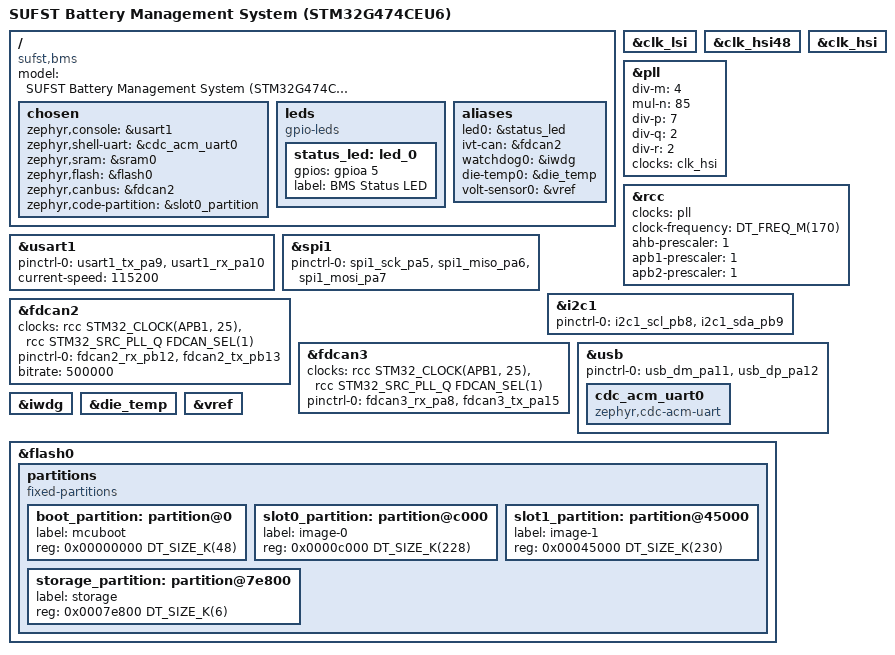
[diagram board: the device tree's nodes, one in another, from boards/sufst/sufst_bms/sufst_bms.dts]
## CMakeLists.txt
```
cmake_minimum_required(VERSION 3.20.0)

# Automatically discover custom boards defined in this repository's boards/ folder
list(APPEND BOARD_ROOT ${CMAKE_CURRENT_SOURCE_DIR})

find_package(Zephyr REQUIRED HINTS $ENV{ZEPHYR_BASE})
project(sufst_bms LANGUAGES C)

target_include_directories(app PRIVATE include)

target_sources(app PRIVATE
    src/main.c
    src/bms_sm.c
    src/bms_safety.c
    src/drv3946.c
    src/bms_hv_sense.c
    src/bms_shell.c
    src/bms_usb.c
    src/ivt_s.c
)
```

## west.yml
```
manifest:
  remotes:
    - name: zephyrproject-rtos
      url-base: https://github.com/zephyrproject-rtos

  defaults:
    remote: zephyrproject-rtos

  projects:
    - name: zephyr
      revision: v4.4.0
      import:
        name-allowlist:
          - cmsis
          - cmsis_6
          - hal_stm32
          - percepio
          - picolibc
          - mcuboot
          - segger
          - mbedtls

  self:
    path: app
```

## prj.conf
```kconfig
# Base Zephyr OS Configuration for SUFST BMS
CONFIG_MAIN_STACK_SIZE=2048
CONFIG_SYSTEM_WORKQUEUE_STACK_SIZE=2048

# Hardware Peripherals
CONFIG_GPIO=y
CONFIG_SPI=y
CONFIG_ADC=y
CONFIG_CAN=y
CONFIG_SERIAL=y
CONFIG_CONSOLE=y
CONFIG_UART_CONSOLE=y

# USB CDC-ACM virtual COM port carrying the Zephyr shell ("bms" commands)
CONFIG_USB_DEVICE_STACK_NEXT=y
CONFIG_CDC_ACM_SERIAL_INITIALIZE_AT_BOOT=y
CONFIG_CDC_ACM_SERIAL_MANUFACTURER_STRING="SUFST"
CONFIG_CDC_ACM_SERIAL_PRODUCT_STRING="SUFST BMS"
CONFIG_CDC_ACM_SERIAL_SELF_POWERED=y
CONFIG_UART_LINE_CTRL=y
CONFIG_SHELL=y
CONFIG_SHELL_BACKEND_SERIAL_CHECK_DTR=y

# Logging
CONFIG_LOG=y
CONFIG_LOG_DEFAULT_LEVEL=3
```

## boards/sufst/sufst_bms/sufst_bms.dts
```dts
/*
 * SUFST BMS Custom Board DeviceTree (STM32G474CEU6 - UFQFPN48)
 * SPDX-License-Identifier: Apache-2.0
 */

/dts-v1/;
#include <st/g4/stm32g474Xe.dtsi>
#include <st/g4/stm32g474c(b-c-e)ux-pinctrl.dtsi>

/ {
	model = "SUFST Battery Management System (STM32G474CEU6)";
	compatible = "sufst,bms", "st,stm32g474";

	chosen {
		zephyr,console = &usart1;
		zephyr,shell-uart = &cdc_acm_uart0;
		zephyr,sram = &sram0;
		zephyr,flash = &flash0;
		zephyr,canbus = &fdcan2;
		zephyr,code-partition = &slot0_partition;
	};

	leds: leds {
		compatible = "gpio-leds";

		status_led: led_0 {
			/* Update pin to match BMS schematic status LED */
			gpios = <&gpioa 5 GPIO_ACTIVE_HIGH>;
			label = "BMS Status LED";
		};
	};

	aliases {
		led0 = &status_led;
		ivt-can = &fdcan2;
		watchdog0 = &iwdg;
		die-temp0 = &die_temp;
		volt-sensor0 = &vref;
	};
};

&clk_lsi {
	status = "okay";
};

&clk_hsi48 {
	status = "okay";
};

/*
 * Default clock setup uses internal 16 MHz HSI -> PLL -> 170 MHz SYSCLK
 * so the board boots without depending on an external crystal.
 * When using an external HSE crystal on the PCB, enable &clk_hse and
 * switch &pll clocks to <&clk_hse>.
 */
&clk_hsi {
	status = "okay";
};

&pll {
	div-m = <4>;
	mul-n = <85>;
	div-p = <7>;
	div-q = <2>;
	div-r = <2>;
	clocks = <&clk_hsi>;
	status = "okay";
};

&rcc {
	clocks = <&pll>;
	clock-frequency = <DT_FREQ_M(170)>;
	ahb-prescaler = <1>;
	apb1-prescaler = <1>;
	apb2-prescaler = <1>;
};

&usart1 {
	pinctrl-0 = <&usart1_tx_pa9 &usart1_rx_pa10>;
	pinctrl-names = "default";
	current-speed = <115200>;
	status = "okay";
};

&spi1 {
	pinctrl-0 = <&spi1_sck_pa5 &spi1_miso_pa6 &spi1_mosi_pa7>;
	pinctrl-names = "default";
	status = "okay";
};

&i2c1 {
	pinctrl-0 = <&i2c1_scl_pb8 &i2c1_sda_pb9>;
	pinctrl-names = "default";
	status = "okay";
};

/*
 * PA11 / PA12 are the only USB D- / D+ pins on the 48-pin package, so CAN
 * uses FDCAN2 and FDCAN3 instead of FDCAN1. Pin choices are placeholders
 * until the PCB is final (alternatives: FDCAN2 on PB5/PB6, FDCAN3 on PB3/PB4,
 * FDCAN1 on PB8/PB9 - note PB8 is BOOT0).
 */
&fdcan2 {
	clocks = <&rcc STM32_CLOCK(APB1, 25)>,
		 <&rcc STM32_SRC_PLL_Q FDCAN_SEL(1)>;
	pinctrl-0 = <&fdcan2_rx_pb12 &fdcan2_tx_pb13>;
	pinctrl-names = "default";
	bitrate = <500000>; /* IVT-S factory default */
	status = "okay";
};

&fdcan3 {
	clocks = <&rcc STM32_CLOCK(APB1, 25)>,
		 <&rcc STM32_SRC_PLL_Q FDCAN_SEL(1)>;
	pinctrl-0 = <&fdcan3_rx_pa8 &fdcan3_tx_pa15>;
	pinctrl-names = "default";
	status = "okay";
};

/*
 * USB full-speed device, clocked from HSI48 (default CLK48 source). HSI48 is
 * trimmed against USB SOF by the CRS, enabled in src/bms_usb.c.
 */
zephyr_udc0: &usb {
	pinctrl-0 = <&usb_dm_pa11 &usb_dp_pa12>;
	pinctrl-names = "default";
	status = "okay";

	cdc_acm_uart0: cdc_acm_uart0 {
		compatible = "zephyr,cdc-acm-uart";
	};
};

&iwdg {
	status = "okay";
};

&die_temp {
	status = "okay";
};

&vref {
	status = "okay";
};

&flash0 {
	partitions {
		compatible = "fixed-partitions";
		#address-cells = <1>;
		#size-cells = <1>;

		boot_partition: partition@0 {
			label = "mcuboot";
			reg = <0x00000000 DT_SIZE_K(48)>;
		};

		slot0_partition: partition@c000 {
			label = "image-0";
			reg = <0x0000c000 DT_SIZE_K(228)>;
		};

		slot1_partition: partition@45000 {
			label = "image-1";
			reg = <0x00045000 DT_SIZE_K(230)>;
		};

		storage_partition: partition@7e800 {
			label = "storage";
			reg = <0x0007e800 DT_SIZE_K(6)>;
		};
	};
};
```

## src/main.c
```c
#include <zephyr/kernel.h>
#include <zephyr/logging/log.h>

#include "bms.h"

LOG_MODULE_REGISTER(bms_main, LOG_LEVEL_INF);

static struct bms_ctx bms;
static K_MUTEX_DEFINE(bms_mutex);

struct bms_ctx *bms_ctx_get(void)
{
	return &bms;
}

void bms_ctx_lock(void)
{
	k_mutex_lock(&bms_mutex, K_FOREVER);
}

void bms_ctx_unlock(void)
{
	k_mutex_unlock(&bms_mutex);
}

/**
 * @brief Temporary stub to populate nominal cell & AMC3330 measurements
 *        until the physical ADC/GPIO pins and AFE driver are wired up.
 */
static void update_mock_measurements(struct bms_ctx *ctx)
{
	ctx->afe_init_ok      = true;
	ctx->last_afe_rx_ms   = k_uptime_get();
	ctx->min_cell_mv      = 3700U;   /* 3.70 V */
	ctx->max_cell_mv      = 3720U;   /* 3.72 V */
	ctx->min_temp_deci_c  = 240;     /* 24.0 C */
	ctx->max_temp_deci_c  = 265;     /* 26.5 C */
	ctx->sum_cells_mv     = 371000U; /* 371.0 V */

	/* Mock AMC3330 U4 (ACCU) & U3 (DC-LINK) differential outputs + DIAG pins */
	ctx->hv_sense.accu.mock_diag_ok   = true;
	ctx->hv_sense.accu.mock_diff_mv   = amc3330_hv_mv_to_diff_mv(371000U); /* ~1067 mV diff */
	ctx->hv_sense.dclink.mock_diag_ok = true;
	ctx->hv_sense.dclink.mock_diff_mv = amc3330_hv_mv_to_diff_mv(0U);      /* 0 V when AIRs open */
}

/**
 * @brief Pull the latest IVT-S readings into the BMS context.
 */
static void update_current_measurement(struct bms_ctx *ctx)
{
	ivt_s_get(&ctx->ivt);

	if (ctx->ivt.ch[IVT_S_CH_I].seen) {
		ctx->pack_current_ma   = BMS_CURRENT_SENSOR_SIGN * ctx->ivt.ch[IVT_S_CH_I].value;
		ctx->current_sensor_ok = true;
	}
}

int main(void)
{
	LOG_INF("SUFST BMS Firmware Initialized (%s)", CONFIG_BOARD_TARGET);

	bms_ctx_lock();
	bms_sm_init(&bms);
	bms_ctx_unlock();

	if (ivt_s_init() < 0) {
		LOG_ERR("IVT-S current sensor CAN init failed; BMS will stay in INIT");
	}

	while (1) {
		bms_ctx_lock();
		update_mock_measurements(&bms);
		update_current_measurement(&bms);
		bms_sm_tick(&bms);
		bms_safety_check(&bms, BMS_SM_TICK_MS);
		bms_ctx_unlock();

		k_sleep(K_MSEC(BMS_SM_TICK_MS));
	}

	return 0;
}
```

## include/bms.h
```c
#ifndef SUFST_BMS_H_
#define SUFST_BMS_H_

/**
 * @file bms.h
 * @brief SUFST BMS core data structures, safety limits, fault flags,
 *        and state machine / safety monitor API.
 */

#include <stdbool.h>
#include <stdint.h>

#include "bms_hv_sense.h"
#include "drv3946.h"
#include "ivt_s.h"

/* ==========================================================================
 * Timing & Precharge Configuration Constants
 * ========================================================================== */

/** Periodic state machine & safety monitor tick interval (ms) */
#define BMS_SM_TICK_MS                     50U

/** Mechanical relay settling delay between sequenced contactor steps (ms) */
#define BMS_RELAY_SETTLE_MS                100U

/** Maximum allowed time in PRECHARGE_WAIT before faulting (ms) */
#define BMS_PRECHARGE_TIMEOUT_MS           3000U

/** Minimum time in PRECHARGE_WAIT before checking voltage threshold (ms) */
#define BMS_PRECHARGE_MIN_TIME_MS          500U

/** Precharge complete threshold: TS voltage >= 95% of pack voltage */
#define BMS_PRECHARGE_THRESHOLD_PCT        95U

/* ==========================================================================
 * Safety Threshold Constants (Standard Li-Ion / Formula Student EV Defaults)
 * ========================================================================== */

/** Maximum allowed single cell voltage (4.200 V) */
#define BMS_CELL_MAX_MV                    4200U

/** Minimum allowed single cell voltage (2.500 V) */
#define BMS_CELL_MIN_MV                    2500U

/** Implausibly high cell reading -> sensor/sense-wire fault (5.000 V) */
#define BMS_CELL_IMPLAUSIBLE_HIGH_MV       5000U

/** Implausibly low cell reading -> sensor/sense-wire fault (0.500 V) */
#define BMS_CELL_IMPLAUSIBLE_LOW_MV        500U

/** Maximum allowed cell temperature in 0.1 deg C (60.0 C per FS EV rules) */
#define BMS_TEMP_MAX_DECI_C                600

/** Minimum allowed cell temperature in 0.1 deg C (-20.0 C) */
#define BMS_TEMP_MIN_DECI_C                (-200)

/** Implausibly high temperature reading in 0.1 deg C (120.0 C, shorted NTC) */
#define BMS_TEMP_IMPLAUSIBLE_HIGH_DECI_C   1200

/** Implausibly low temperature reading in 0.1 deg C (-40.0 C, open NTC) */
#define BMS_TEMP_IMPLAUSIBLE_LOW_DECI_C    (-400)

/**
 * Maximum allowed discharge current in mA (200.0 A, pack_current_ma > +limit).
 * Set by the inverter's maximum DC current draw.
 */
#define BMS_CURRENT_MAX_DISCHARGE_MA       200000

/**
 * Maximum allowed regen / charge current in mA (40.5 A, pack_current_ma < -limit).
 * Pack is 140s3p Molicel INR-21700-P45B: 13.5 A max charge per cell x 3 parallel.
 */
#define BMS_CURRENT_MAX_REGEN_MA           40500

/**
 * Sign applied to the IVT-S current reading so that positive = discharge.
 * Set to -1 if the sensor is mounted with its current direction reversed.
 */
#define BMS_CURRENT_SENSOR_SIGN            1

/** Charge current magnitude above which the pack counts as "charging" (1.0 A) */
#define BMS_CHARGE_DETECT_MA               1000

/** Minimum cell temperature for charging / regen in 0.1 deg C (0.0 C) */
#define BMS_TEMP_CHARGE_MIN_DECI_C         0

/* ==========================================================================
 * Regen Derating Window (advisory limit broadcast to VCU / inverter)
 *
 * The limit ramps linearly from BMS_CURRENT_MAX_REGEN_MA at the "FULL" point
 * down to 0 at the "ZERO" point. Each ZERO point sits inside its hard fault
 * threshold so a compliant inverter never trips the BMS.
 * ========================================================================== */

/** Highest cell voltage at which full regen is still allowed (4.100 V) */
#define BMS_REGEN_FULL_CELL_MV             4100

/** Highest cell voltage at which regen is cut to zero (4.180 V) */
#define BMS_REGEN_ZERO_CELL_MV             4180

/** Lowest cell temperature at which full regen is allowed (10.0 C) */
#define BMS_REGEN_FULL_COLD_DECI_C         100

/** Lowest cell temperature at which regen is cut to zero (2.0 C) */
#define BMS_REGEN_ZERO_COLD_DECI_C         20

/** Highest cell temperature at which full regen is allowed (50.0 C) */
#define BMS_REGEN_FULL_HOT_DECI_C          500

/** Highest cell temperature at which regen is cut to zero (58.0 C) */
#define BMS_REGEN_ZERO_HOT_DECI_C          580

/** Maximum allowed mismatch between sum of cells and HV pack sensor (5.0 V) */
#define BMS_PACK_SUM_MAX_MISMATCH_MV       5000U

/* ==========================================================================
 * Fault Debounce Timings (FS EV Rule Compliant)
 * ========================================================================== */

/** Over/under-voltage debounce duration (ms) - FS max allowed: 500 ms */
#define BMS_DEBOUNCE_VOLTAGE_MS            100U

/** Over-current debounce duration (ms) - FS max allowed: 500 ms */
#define BMS_DEBOUNCE_CURRENT_MS            100U

/** Over/under-temperature debounce duration (ms) - FS max allowed: 1000 ms */
#define BMS_DEBOUNCE_TEMP_MS               500U

/** Charging below minimum charge temperature debounce duration (ms) */
#define BMS_DEBOUNCE_CHARGE_TEMP_MS        500U

/** Open-wire detection debounce duration (ms) */
#define BMS_DEBOUNCE_OPEN_WIRE_MS          100U

/** Sensor implausibility debounce duration (ms) */
#define BMS_DEBOUNCE_IMPLAUSIBLE_MS        100U

/** Maximum time without a valid AFE update before faulting (ms) */
#define BMS_AFE_COMM_TIMEOUT_MS            250U

/** Maximum time without an IVT-S current frame before faulting (ms, sensor cycle is 20 ms) */
#define BMS_CURRENT_SENSOR_TIMEOUT_MS      100U

/** IVT-S reported result / system error debounce duration (ms) */
#define BMS_DEBOUNCE_CURRENT_SENSOR_MS     100U

/* ==========================================================================
 * BMS States
 * ========================================================================== */

typedef enum {
	BMS_STATE_INIT = 0,            /**< Boot, self-test, and persistent fault check */
	BMS_STATE_STANDBY,             /**< Idle; all relays open, outputs TS_READY when SDC powered */
	BMS_STATE_PRECHARGE_CLOSE_PC,  /**< Step 1: Close Precharge first (PC=1, AIR-=0, AIR+=0) */
	BMS_STATE_PRECHARGE_WAIT,      /**< Step 2: Close AIR- & charge DC bus (PC=1, AIR-=1, AIR+=0) */
	BMS_STATE_PRECHARGE_CLOSE_POS, /**< Step 3: Close AIR+ while PC stays closed (PC=1, AIR-=1, AIR+=1) */
	BMS_STATE_PRECHARGE_OPEN_NEG,  /**< Precharge abort/fault: Open AIR- first (PC=1, AIR-=0, AIR+=0) */
	BMS_STATE_ACTIVE,              /**< Step 4: Open PC, TS active (PC=0, AIR-=1, AIR+=1) */
	BMS_STATE_CHARGING,            /**< Pack charging active (PC=0, AIR-=1, AIR+=1, balancing) */
	BMS_STATE_FAULT,               /**< Fault latched; SDC open, all relays open (PC=0, AIR-=0, AIR+=0) */
} bms_state_t;

/* ==========================================================================
 * Safety Fault Bitmask
 * ========================================================================== */

#define BMS_FAULT_NONE                (0U)
#define BMS_FAULT_CELL_OV             (1U << 0) /**< Cell over-voltage */
#define BMS_FAULT_CELL_UV             (1U << 1) /**< Cell under-voltage */
#define BMS_FAULT_OVER_TEMP           (1U << 2) /**< Cell/pack over-temperature */
#define BMS_FAULT_UNDER_TEMP          (1U << 3) /**< Cell/pack under-temperature */
#define BMS_FAULT_OVER_CURRENT        (1U << 4) /**< Pack discharge over-current */
#define BMS_FAULT_AFE_COMM            (1U << 5) /**< AFE isoSPI communication loss */
#define BMS_FAULT_OPEN_WIRE           (1U << 6) /**< Cell sense/thermistor open wire */
#define BMS_FAULT_PRECHARGE_TIMEOUT   (1U << 7) /**< Precharge failed to reach target V */
#define BMS_FAULT_IMPLAUSIBILITY      (1U << 8) /**< Sensor reading implausibility */
#define BMS_FAULT_CONTACTOR_DRV       (1U << 9) /**< DRV3946-Q1 contactor driver nFAULT / SPI error */
#define BMS_FAULT_REGEN_OVER_CURRENT  (1U << 10) /**< Pack regen / charge over-current */
#define BMS_FAULT_CHARGE_UNDER_TEMP   (1U << 11) /**< Charging / regen below minimum charge temperature */
#define BMS_FAULT_CURRENT_SENSOR      (1U << 12) /**< IVT-S current sensor timeout or reported error */

/* ==========================================================================
 * BMS Context & IO State
 * ========================================================================== */

/**
 * @brief Relay, Shutdown Circuit (SDC), and VCU handshake outputs.
 */
struct bms_outputs {
	bool precharge_closed;     /**< Precharge relay (discrete GPIO) */
	bool air_neg_closed;       /**< Low-side contactor (AIR- via DRV3946 Ch1) */
	bool air_pos_closed;       /**< High-side contactor (AIR+ via DRV3946 Ch2) */
	bool sdc_fault_pin_active; /**< GPIO output: true = open SDC relay (FAULT) */
	bool ts_ready;             /**< BMS -> VCU (CAN/GPIO): AIRs have power & SDC can close */
	bool ts_active;            /**< BMS -> VCU (CAN/GPIO): Precharge complete & both AIRs closed */
	bool balancing_enabled;    /**< Cell balancing active flag */
	bool regen_allowed;        /**< BMS -> VCU (CAN): true when max_regen_current_ma > 0 */
	uint32_t max_regen_current_ma; /**< BMS -> VCU (CAN): derated regen current limit (mA, magnitude) */
};

/**
 * @brief External commands / requests into the BMS state machine (from VCU / PC).
 */
struct bms_requests {
	bool ts_request_can;       /**< VCU -> BMS "TS REQUEST" via CAN */
	bool ts_request_gpio;      /**< VCU -> BMS "TS REQUEST" via GPIO */
	bool ts_request;           /**< Combined effective TS REQUEST signal (CAN || GPIO) */
	bool charge_enable;        /**< Request to enter CHARGING mode after precharge */
	bool pc_clear_faults;      /**< Manual fault-clear command from PC application */
};

/**
 * @brief Accumulator timers (ms) for fault condition debouncing.
 */
struct bms_safety_timers {
	uint32_t cell_ov_ms;
	uint32_t cell_uv_ms;
	uint32_t over_temp_ms;
	uint32_t under_temp_ms;
	uint32_t over_current_ms;
	uint32_t regen_over_current_ms;
	uint32_t charge_under_temp_ms;
	uint32_t current_sensor_ms;
	uint32_t open_wire_ms;
	uint32_t implausibility_ms;
};

/**
 * @brief Main BMS runtime context.
 */
struct bms_ctx {
	bms_state_t state;
	int64_t state_entry_time_ms;

	/* Hardware Drivers: DRV3946-Q1 Contactors & Dual AMC3330 HV Voltage Sense */
	DRV3946_HandleTypeDef drv_airs;
	struct bms_hv_sense   hv_sense;

	/* Fault tracking & debounce state */
	uint32_t live_faults;      /**< Currently present (debounced) fault conditions */
	uint32_t latched_faults;   /**< Persistent fault bitmask (saved across power cycles) */
	struct bms_safety_timers fault_timers;

	/* Shutdown circuit, AFE, & AMC3330 DIAG readiness monitoring */
	bool afe_init_ok;          /**< Set true once AFE passes startup self-check */
	bool hv_sense_valid;       /**< True when both AMC3330 DIAG pins (U3 & U4) are HIGH */
	bool sdc_airs_powered;     /**< Continuous sense: true when SDC is closed & AIRs have power */
	bool afe_open_wire;        /**< Reported by AFE open-wire diagnostic check */
	int64_t last_afe_rx_ms;    /**< Uptime timestamp (ms) of last valid AFE sample */

	/* IVT-S current sensor (CAN) */
	struct ivt_s_data ivt;     /**< Latest IVT-S readings (all channels) */
	bool current_sensor_ok;    /**< Set true once the first IVT-S current frame arrives */

	/* Pack & DC bus measurements (updated by sensor/AFE layer) */
	uint32_t sum_cells_mv;     /**< Sum of all individual cell voltages from AFE (mV) */
	uint32_t pack_voltage_mv;  /**< Total accumulator voltage from HV pack sensor (mV) */
	uint32_t ts_voltage_mv;    /**< Tractive System / inverter DC-link voltage (mV) */
	int32_t  pack_current_ma;  /**< Pack current from IVT-S (mA, positive = discharge) */
	uint16_t min_cell_mv;      /**< Lowest single cell voltage (mV) */
	uint16_t max_cell_mv;      /**< Highest single cell voltage (mV) */
	int16_t  min_temp_deci_c;  /**< Lowest cell temperature (0.1 deg C) */
	int16_t  max_temp_deci_c;  /**< Highest cell temperature (0.1 deg C) */

	struct bms_requests req;
	struct bms_outputs out;
};

/* ==========================================================================
 * State Machine Public API (bms_sm.c)
 * ========================================================================== */

/**
 * @brief Initialize the BMS context, load persistent faults from Flash,
 *        and set safe initial hardware outputs.
 */
void bms_sm_init(struct bms_ctx *ctx);

/**
 * @brief Execute one periodic cycle of the BMS state machine.
 *        Samples SDC / ts_request inputs, updates ts_ready, and runs state transitions.
 */
void bms_sm_tick(struct bms_ctx *ctx);

/**
 * @brief Evaluate whether the BMS is ready for Tractive System activation
 *        (no faults, AFE initialized, and AIRs have power / SDC can close).
 */
bool bms_sm_is_ts_ready(const struct bms_ctx *ctx);

/**
 * @brief Raise one or more safety fault flags. Immediately latches into
 *        non-volatile storage and initiates sequenced fault shutdown.
 */
void bms_sm_raise_fault(struct bms_ctx *ctx, uint32_t fault_mask);

/**
 * @brief Request manual clearance of latched faults (from PC application).
 *        Faults will only clear if live_faults == 0 and ts_request is off.
 */
bool bms_sm_clear_faults_from_pc(struct bms_ctx *ctx);

/**
 * @brief Convert a BMS state enum to a human-readable string.
 */
const char *bms_state_to_str(bms_state_t state);

/* ==========================================================================
 * Safety & Fault Monitor Public API (bms_safety.c)
 * ========================================================================== */

/**
 * @brief Evaluate all cell voltages, temperatures, pack current, open-wire,
 *        sensor plausibility, and AFE communication heartbeat with debouncing.
 *        Updates ctx->live_faults and raises latched faults when thresholds
 *        are exceeded for their respective debounce durations.
 *
 * @param ctx   Pointer to BMS context structure.
 * @param dt_ms Elapsed time since last check in milliseconds (e.g. BMS_SM_TICK_MS).
 */
void bms_safety_check(struct bms_ctx *ctx, uint32_t dt_ms);

/**
 * @brief Compute the derated regen current limit for the current measurements.
 *
 * Returns 0 unless the BMS is in BMS_STATE_ACTIVE with no live or latched
 * faults. Otherwise returns BMS_CURRENT_MAX_REGEN_MA scaled by the most
 * restrictive of the cell-voltage, cold-temperature and hot-temperature
 * derating ramps (see BMS_REGEN_* constants).
 *
 * @param ctx Pointer to BMS context structure.
 * @return Allowed regen current magnitude in mA.
 */
uint32_t bms_regen_limit_ma(const struct bms_ctx *ctx);

/* ==========================================================================
 * Shared Context Access (main.c)
 * ========================================================================== */

/**
 * @brief Get the single BMS context owned by the main control loop.
 *        Hold bms_ctx_lock() while reading or modifying it from another thread.
 */
struct bms_ctx *bms_ctx_get(void);

/** @brief Lock the BMS context (held by the main loop for each control tick). */
void bms_ctx_lock(void);

/** @brief Unlock the BMS context. */
void bms_ctx_unlock(void);

#endif /* SUFST_BMS_H_ */
```

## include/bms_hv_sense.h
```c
/**
 * @file bms_hv_sense.h
 * @brief AMC3330DWER Isolated High-Voltage Sensing Driver (Accumulator & DC-Link).
 *
 * Schematic Parameters (U3 = DC-Link TS, U4 = Accumulator TS):
 *   - High-side top divider:    4 x 422 kOhm in series = 1,688,000 Ohm
 *     (U3: R13+R14+R16+R18, U4: R22+R23+R25+R27)
 *   - High-side sense resistor: 2.43 kOhm = 2,430 Ohm
 *     (U3: R20, U4: R29)
 *   - AMC3330 nominal gain:     G = 2.0 V/V
 *   - Output filter:            2 x 100 Ohm + 1 nF differential RC filter
 *   - DIAG output (Pin 14):     Open-drain with 47 kOhm pull-up to +3V3
 *                               HIGH (1) = Valid reading
 *                               LOW  (0) = Invalid reading (startup / fault)
 *
 * Transfer Function:
 *   V_diff = V_OUTP - V_OUTN = 2.0 * V_HV * (R_bot / (R_top + R_bot))
 *   V_HV   = V_diff * (R_top + R_bot) / (2.0 * R_bot)
 *          = V_diff * (1,688,000 + 2,430) / (2 * 2,430)
 *          = V_diff * 1,690,430 / 4,860
 *          ~= V_diff * 347.8251
 */

#ifndef SUFST_BMS_HV_SENSE_H_
#define SUFST_BMS_HV_SENSE_H_

#include <stdbool.h>
#include <stdint.h>
#include <zephyr/drivers/adc.h>
#include <zephyr/drivers/gpio.h>

#ifdef __cplusplus
extern "C" {
#endif

/* ==========================================================================
 * Schematic Resistor & AMC3330 Constants
 * ========================================================================== */

/** Top series divider resistance: 4 * 422 kOhm = 1,688,000 Ohm */
#define AMC3330_R_TOP_OHM          (4ULL * 422000ULL)

/** Bottom sense resistance: 2.43 kOhm = 2,430 Ohm */
#define AMC3330_R_BOT_OHM          (2430ULL)

/** AMC3330 fixed differential voltage gain (2 V/V) */
#define AMC3330_GAIN_NUM           (2ULL)

/** Numerator for V_diff -> V_HV conversion: R_top + R_bot = 1,690,430 */
#define AMC3330_SCALE_NUM          (AMC3330_R_TOP_OHM + AMC3330_R_BOT_OHM)

/** Denominator for V_diff -> V_HV conversion: Gain * R_bot = 4,860 */
#define AMC3330_SCALE_DEN          (AMC3330_GAIN_NUM * AMC3330_R_BOT_OHM)

/* ==========================================================================
 * Data Structures
 * ========================================================================== */

/**
 * @brief Single AMC3330DWER isolated voltage sensor channel descriptor.
 *
 * Pinout-independent: if adc_ch.dev == NULL or diag_gpio.port == NULL
 * (before MCU pinout is finalized), the driver uses simulated/mock values.
 */
struct amc3330_chan {
	struct adc_dt_spec  adc_ch;        /**< Differential STM32 ADC channel (OUTP - OUTN) */
	struct gpio_dt_spec diag_gpio;     /**< DIAG input pin (High = Valid, Low = Invalid) */

	/* Mock / fallback values used when hardware pins are not yet bound */
	int32_t             mock_diff_mv;  /**< Simulated differential output (V_OUTP - V_OUTN) in mV */
	bool                mock_diag_ok;  /**< Simulated DIAG state when diag_gpio.port == NULL */

	/* Latest sampled outputs */
	int32_t             diff_mv;       /**< Measured differential output (V_OUTP - V_OUTN) in mV */
	uint32_t            hv_mv;         /**< Calculated high-side voltage in mV */
	bool                diag_valid;    /**< True if DIAG pin is HIGH (valid reading) */
};

/**
 * @brief Dual AMC3330 HV sensing context (U4 Accumulator & U3 DC-Link).
 */
struct bms_hv_sense {
	struct amc3330_chan accu;          /**< U4: Accumulator side (ACCU TS+ / ACCU TS-) */
	struct amc3330_chan dclink;        /**< U3: Tractive System / Inverter side (DC-LINK TS+ / TS-) */
};

/* ==========================================================================
 * Public API
 * ========================================================================== */

/**
 * @brief Initialize both AMC3330 channels (ADC channels & DIAG GPIOs if bound).
 *
 * @param hv Pointer to HV sensing structure.
 * @return 0 on success, negative errno on hardware configuration failure.
 */
int bms_hv_sense_init(struct bms_hv_sense *hv);

/**
 * @brief Sample DIAG pins and differential ADC channels for both U3 (DC-Link)
 *        and U4 (Accumulator), and convert to high-voltage millivolts.
 *
 * @param hv Pointer to HV sensing structure.
 * @return 0 on success, negative errno on ADC read error.
 */
int bms_hv_sense_sample(struct bms_hv_sense *hv);

/**
 * @brief Convert AMC3330 differential output voltage (V_OUTP - V_OUTN in mV)
 *        to high-side bus voltage (in mV) using the schematic divider ratio.
 *
 * @param diff_mv Differential voltage (V_OUTP - V_OUTN) in millivolts.
 * @return High-side voltage in millivolts (clamped to >= 0 mV).
 */
uint32_t amc3330_diff_mv_to_hv_mv(int32_t diff_mv);

/**
 * @brief Convert a high-side bus voltage (in mV) to the expected AMC3330
 *        differential output voltage (V_OUTP - V_OUTN in mV). Useful for testing.
 */
int32_t amc3330_hv_mv_to_diff_mv(uint32_t hv_mv);

#ifdef __cplusplus
}
#endif

#endif /* SUFST_BMS_HV_SENSE_H_ */
```

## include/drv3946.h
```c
/**
 * @file drv3946.h
 * @brief TI DRV3946-Q1 Dual-Channel Contactor / Solenoid Driver for Zephyr RTOS.
 *
 * Ported from SUFST STM32 DRV3946-Q1 driver to Zephyr RTOS.
 * Hardware-agnostic: uses Zephyr's generic spi_dt_spec and gpio_dt_spec pointers,
 * so it does not depend on any specific SPI peripheral (SPI1/SPI2/SPI3) or pinout.
 * If no SPI bus / GPIO pins are attached yet (bus == NULL / port == NULL), the
 * driver safely operates in unbound/stubbed hardware mode until PCB bring-up.
 */

#ifndef SUFST_DRV3946_H_
#define SUFST_DRV3946_H_

#include <stdbool.h>
#include <stdint.h>
#include <zephyr/drivers/gpio.h>
#include <zephyr/drivers/spi.h>

#ifdef __cplusplus
extern "C" {
#endif

/* ==========================================================================
 * DRV3946-Q1 SPI Register Map Definitions
 * ========================================================================== */

#define DRV3946_REG_STATUS0        0x01U
#define DRV3946_REG_STATUS1        0x02U
#define DRV3946_REG_STATUS2        0x03U
#define DRV3946_REG_STATUS3        0x04U
#define DRV3946_REG_STATUS4        0x0AU
#define DRV3946_REG_STATUS5        0x0BU

#define DRV3946_REG_MEAS0          0x05U
#define DRV3946_REG_MEAS1          0x06U
#define DRV3946_REG_MEAS2          0x07U
#define DRV3946_REG_MEAS3          0x08U
#define DRV3946_REG_MEAS4          0x09U
#define DRV3946_REG_MEAS5          0x0CU
#define DRV3946_REG_MEAS6          0x0DU

#define DRV3946_REG_CONFIGA0       0x10U
#define DRV3946_REG_CONFIGA1       0x11U
#define DRV3946_REG_CONFIGA2       0x12U
#define DRV3946_REG_CONFIGA3       0x13U
#define DRV3946_REG_CONFIGA4       0x14U
#define DRV3946_REG_CONFIGA5       0x15U
#define DRV3946_REG_CONFIGA6       0x16U

#define DRV3946_REG_CONFIGB0       0x17U
#define DRV3946_REG_CONFIGB1       0x18U
#define DRV3946_REG_CONFIGB2       0x19U
#define DRV3946_REG_CONFIGB3       0x1AU
#define DRV3946_REG_CONFIGB4       0x1BU

#define DRV3946_REG_CMD0           0x1CU
#define DRV3946_REG_CMD1           0x1DU
#define DRV3946_REG_CMD2           0x1EU

/* ==========================================================================
 * Bitfields & Constants
 * ========================================================================== */

#define DRV3946_SPI_RW_READ        0x01U
#define DRV3946_SPI_RW_WRITE       0x00U
#define DRV3946_CMD_CLEAR_FAULT    0x8000U
#define DRV3946_CMD_BIST_RUN       0x4000U

typedef enum {
	DRV3946_OK      = 0x00U,
	DRV3946_ERROR   = 0x01U,
	DRV3946_BUSY    = 0x02U,
	DRV3946_TIMEOUT = 0x03U,
	DRV3946_CRC_ERR = 0x04U
} DRV3946_Status_t;

typedef enum {
	DRV3946_CHANNEL_1    = 0x01U, /**< Channel 1: Negative AIR (AIR-) */
	DRV3946_CHANNEL_2    = 0x02U, /**< Channel 2: Positive AIR (AIR+) */
	DRV3946_CHANNEL_BOTH = 0x03U
} DRV3946_Channel_t;

typedef enum {
	CONTACTOR_OPEN   = 0x00U,
	CONTACTOR_CLOSED = 0x01U
} Contactor_State_t;

/**
 * @brief DRV3946-Q1 Device Handle Struct (Zephyr hardware-agnostic)
 *
 * Note: Any SPI bus (SPI1, SPI2, SPI3, etc.) and any GPIO pins can be bound here
 * once the MCU pinout is finalized. If left zero-initialized (spi.bus == NULL),
 * the driver runs safely without touching physical hardware.
 */
typedef struct {
	/* Generic Zephyr SPI & GPIO descriptors (optional until pinout is finalized) */
	struct spi_dt_spec  spi;         /**< Generic SPI bus + CS spec (any SPI peripheral) */
	struct gpio_dt_spec en1_gpio;    /**< ENABLE1 GPIO (Channel 1 -> AIR-) */
	struct gpio_dt_spec en2_gpio;    /**< ENABLE2 GPIO (Channel 2 -> AIR+) */
	struct gpio_dt_spec nfault_gpio; /**< nFAULT GPIO (Input, active-low fault from DRV3946) */

	uint8_t             nad;         /**< Node Address (0..3) for addressable SPI */

	/* Local Shadow Memory of Configuration Registers */
	uint16_t            configA[7];  /**< CONFIGA0 .. CONFIGA6 */
	uint16_t            configB[5];  /**< CONFIGB0 .. CONFIGB4 */

	/* Cached Status & Output State */
	uint16_t            last_status[6]; /**< STATUS0 .. STATUS5 */
	Contactor_State_t   ch1_state;      /**< Current commanded state of Channel 1 (AIR-) */
	Contactor_State_t   ch2_state;      /**< Current commanded state of Channel 2 (AIR+) */
	bool                fault_active;   /**< Cached fault state from nFAULT pin / status */
} DRV3946_HandleTypeDef;

/* ==========================================================================
 * Driver Public API
 * ========================================================================== */

/**
 * @brief Initialize the DRV3946 handle, configure GPIOs (if bound),
 *        validate the SPI link, clear POR faults, and read initial status.
 */
DRV3946_Status_t DRV3946_Init(DRV3946_HandleTypeDef *hdrv);

/**
 * @brief Raw 24-bit SPI register read.
 */
DRV3946_Status_t DRV3946_ReadRegister(DRV3946_HandleTypeDef *hdrv,
				      uint8_t reg_addr,
				      uint16_t *reg_data);

/**
 * @brief Raw 24-bit SPI register write with automatic CRC-8 (0x2F) calculation
 *        for CMDx, CONFIGA, and CONFIGB register blocks.
 */
DRV3946_Status_t DRV3946_WriteRegister(DRV3946_HandleTypeDef *hdrv,
				       uint8_t reg_addr,
				       uint16_t reg_data);

/**
 * @brief Control contactor state (Open/Close) using hardware ENABLE1/ENABLE2 pins.
 */
void DRV3946_SetContactorState(DRV3946_HandleTypeDef *hdrv,
			       DRV3946_Channel_t channel,
			       Contactor_State_t state);

/**
 * @brief Immediately force both DRV3946 channels OPEN (ENABLE1 = 0, ENABLE2 = 0).
 */
void DRV3946_EmergencyOpenAll(DRV3946_HandleTypeDef *hdrv);

/**
 * @brief Poll the hardware nFAULT pin (active low) and update cached fault state.
 * @return true if DRV3946 nFAULT is asserted, false otherwise.
 */
bool DRV3946_IsFaultAsserted(DRV3946_HandleTypeDef *hdrv);

/**
 * @brief Read all STATUS registers (STATUS0..STATUS5) over SPI.
 */
DRV3946_Status_t DRV3946_UpdateStatus(DRV3946_HandleTypeDef *hdrv);

/**
 * @brief Clear latched faults on the DRV3946 using CMD1 (0x8000) with CRC-8.
 */
DRV3946_Status_t DRV3946_ClearFaults(DRV3946_HandleTypeDef *hdrv);

/**
 * @brief Read raw 10-bit coil current measurement from MEAS0 (Ch1) or MEAS2 (Ch2).
 */
DRV3946_Status_t DRV3946_ReadCurrentRaw(DRV3946_HandleTypeDef *hdrv,
					DRV3946_Channel_t ch,
					uint16_t *current_raw);

/**
 * @brief Configure peak-and-hold profile and fast demagnetization timings
 *        tailored for Littelfuse DCNLEV100 contactors (~460 mA peak inrush for
 *        50 ms, ~180 mA hold current, and active freewheeling clamp).
 */
DRV3946_Status_t DRV3946_ConfigureDCNLEV100(DRV3946_HandleTypeDef *hdrv,
					    DRV3946_Channel_t channel);

#ifdef __cplusplus
}
#endif

#endif /* SUFST_DRV3946_H_ */
```

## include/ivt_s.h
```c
#ifndef SUFST_IVT_S_H_
#define SUFST_IVT_S_H_

/**
 * @file ivt_s.h
 * @brief Isabellenhuette IVT-S current / voltage sensor (CAN) receive driver.
 *
 * Decodes the sensor's cyclic result messages (datasheet v1.01, chapter 8.1)
 * using its factory-default configuration:
 *   - 500 kbit/s, 11-bit IDs 0x521 (I) .. 0x528 (Wh), DLC 6
 *   - DB0      MuxID 0x00..0x07 (channel number)
 *   - DB1      low nibble: per-channel cyclic message counter
 *              high nibble: state bits (IVT_S_STATE_*)
 *   - DB2..5   signed 32-bit result, big endian
 *   - Current cyclic every 20 ms, U1..U3 cyclic every 60 ms, rest disabled
 */

#include <stdbool.h>
#include <stddef.h>
#include <stdint.h>

/** Default CAN ID of IVT_Msg_Result_I; the other results follow consecutively */
#define IVT_S_CAN_ID_RESULT_BASE   0x521U

/** Result payload length (bytes) */
#define IVT_S_RESULT_DLC           6U

/** Result channels, equal to the MuxID in DB0 */
enum ivt_s_channel {
	IVT_S_CH_I = 0,   /**< Current, 1 mA */
	IVT_S_CH_U1,      /**< Voltage 1, 1 mV */
	IVT_S_CH_U2,      /**< Voltage 2, 1 mV */
	IVT_S_CH_U3,      /**< Voltage 3, 1 mV */
	IVT_S_CH_T,       /**< Temperature, 0.1 deg C */
	IVT_S_CH_W,       /**< Power, 1 W */
	IVT_S_CH_AS,      /**< Current counter, 1 As */
	IVT_S_CH_WH,      /**< Energy counter, 1 Wh */
	IVT_S_CH_COUNT,
};

/* State bits (DB1 high nibble, shifted down to bits 0..3) */
#define IVT_S_STATE_OCS            (1U << 0) /**< Over-current signal is active */
#define IVT_S_STATE_RESULT_ERROR   (1U << 1) /**< This result: out of range / reduced precision / measurement error */
#define IVT_S_STATE_ANY_MEAS_ERROR (1U << 2) /**< Any result has a measurement error */
#define IVT_S_STATE_SYSTEM_ERROR   (1U << 3) /**< System error: sensor function not ensured */

/** One decoded result message */
struct ivt_s_result {
	enum ivt_s_channel channel;
	uint8_t msg_count;   /**< Cyclic counter 0..15 */
	uint8_t state;       /**< IVT_S_STATE_* bits */
	int32_t value;       /**< Raw result in the channel's unit */
};

/** Latest reading of one channel */
struct ivt_s_reading {
	bool     seen;       /**< True once at least one frame has been received */
	int64_t  rx_ms;      /**< Uptime (ms) of the last frame */
	uint8_t  state;      /**< IVT_S_STATE_* bits of the last frame */
	int32_t  value;      /**< Last result in the channel's unit */
};

/** Snapshot of all channels */
struct ivt_s_data {
	struct ivt_s_reading ch[IVT_S_CH_COUNT];
};

/**
 * @brief Decode one IVT-S result message payload (big-endian default config).
 *
 * @param data Frame payload.
 * @param dlc  Frame payload length.
 * @param out  Decoded result.
 * @return true if the payload is a valid result message.
 */
static inline bool ivt_s_decode(const uint8_t *data, uint8_t dlc, struct ivt_s_result *out)
{
	if (dlc < IVT_S_RESULT_DLC || data[0] >= IVT_S_CH_COUNT) {
		return false;
	}

	out->channel   = (enum ivt_s_channel)data[0];
	out->msg_count = data[1] & 0x0FU;
	out->state     = data[1] >> 4;
	out->value     = (int32_t)(((uint32_t)data[2] << 24) |
				   ((uint32_t)data[3] << 16) |
				   ((uint32_t)data[4] << 8)  |
				    (uint32_t)data[5]);
	return true;
}

/**
 * @brief Start the CAN controller and begin receiving IVT-S result messages.
 * @return 0 on success, negative errno otherwise.
 */
int ivt_s_init(void);

/**
 * @brief Copy the latest readings of all channels.
 */
void ivt_s_get(struct ivt_s_data *out);

#endif /* SUFST_IVT_S_H_ */
```

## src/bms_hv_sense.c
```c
/**
 * @file bms_hv_sense.c
 * @brief AMC3330DWER Isolated High-Voltage Sensing Implementation.
 *
 * Handles both AMC3330 channels from the schematic:
 *   - U4 (accu):   Measures ACCU TS+ to ACCU TS- (before contactors)
 *   - U3 (dclink): Measures DC-LINK TS+ to DC-LINK TS- (after contactors / inverter side)
 *
 * Each channel validates its reading via the AMC3330 DIAG pin (HIGH = valid,
 * LOW = invalid at power-up or high-side fault) before converting the
 * differential analog output (OUTP - OUTN) into millivolts.
 */

#include <zephyr/kernel.h>
#include <zephyr/logging/log.h>

#include "bms_hv_sense.h"

LOG_MODULE_REGISTER(bms_hv_sense, LOG_LEVEL_INF);

/* ==========================================================================
 * Scaling Helpers (Exact 64-bit Integer Math with Rounding)
 * ========================================================================== */

uint32_t amc3330_diff_mv_to_hv_mv(int32_t diff_mv)
{
	/* Clamp small negative ADC offset noise to 0 mV */
	if (diff_mv <= 0) {
		return 0U;
	}

	/*
	 * V_HV (mV) = diff_mv * (R_top + R_bot) / (Gain * R_bot)
	 *           = diff_mv * 1,690,430 / 4,860
	 */
	uint64_t num = ((uint64_t)diff_mv * AMC3330_SCALE_NUM) + (AMC3330_SCALE_DEN / 2ULL);
	return (uint32_t)(num / AMC3330_SCALE_DEN);
}

int32_t amc3330_hv_mv_to_diff_mv(uint32_t hv_mv)
{
	uint64_t num = ((uint64_t)hv_mv * AMC3330_SCALE_DEN) + (AMC3330_SCALE_NUM / 2ULL);
	return (int32_t)(num / AMC3330_SCALE_NUM);
}

/* ==========================================================================
 * Per-Channel Hardware Helpers
 * ========================================================================== */

static int init_single_channel(struct amc3330_chan *ch, const char *name)
{
	/* 1. Configure DIAG input pin if bound in DeviceTree */
	if (ch->diag_gpio.port != NULL) {
		if (!gpio_is_ready_dt(&ch->diag_gpio)) {
			LOG_ERR("AMC3330 %s DIAG GPIO device not ready", name);
			return -ENODEV;
		}
		int ret = gpio_pin_configure_dt(&ch->diag_gpio, GPIO_INPUT);
		if (ret < 0) {
			LOG_ERR("Failed to configure AMC3330 %s DIAG GPIO (%d)", name, ret);
			return ret;
		}
	}

	/* 2. Configure differential ADC channel if bound in DeviceTree */
	if (ch->adc_ch.dev != NULL) {
		if (!adc_is_ready_dt(&ch->adc_ch)) {
			LOG_ERR("AMC3330 %s ADC device not ready", name);
			return -ENODEV;
		}
		int ret = adc_channel_setup_dt(&ch->adc_ch);
		if (ret < 0) {
			LOG_ERR("Failed to setup AMC3330 %s ADC channel (%d)", name, ret);
			return ret;
		}
	}

	LOG_INF("AMC3330 %s channel initialized (%s mode)",
		name,
		(ch->adc_ch.dev != NULL) ? "hardware ADC" : "unbound/mock");

	return 0;
}

static int sample_single_channel(struct amc3330_chan *ch)
{
	/* 1. Validate DIAG pin first (HIGH = valid, LOW = invalid / power-up) */
	if (ch->diag_gpio.port != NULL) {
		ch->diag_valid = (gpio_pin_get_dt(&ch->diag_gpio) > 0);
	} else {
		ch->diag_valid = ch->mock_diag_ok;
	}

	/*
	 * If DIAG is LOW (e.g. AMC3330 isolated DC/DC still powering up or
	 * high-side fault), do not trust the analog output.
	 */
	if (!ch->diag_valid) {
		ch->diff_mv = 0;
		ch->hv_mv   = 0U;
		return 0;
	}

	/* 2. Read differential analog output (OUTP - OUTN) */
	if (ch->adc_ch.dev != NULL) {
		int16_t raw_sample = 0;
		struct adc_sequence seq = {
			.buffer      = &raw_sample,
			.buffer_size = sizeof(raw_sample),
		};

		adc_sequence_init_dt(&ch->adc_ch, &seq);

		int ret = adc_read_dt(&ch->adc_ch, &seq);
		if (ret < 0) {
			ch->diag_valid = false;
			ch->hv_mv      = 0U;
			return ret;
		}

		int32_t val_mv = (int32_t)raw_sample;
		ret = adc_raw_to_millivolts_dt(&ch->adc_ch, &val_mv);
		if (ret < 0) {
			ch->diag_valid = false;
			ch->hv_mv      = 0U;
			return ret;
		}

		ch->diff_mv = val_mv;
	} else {
		ch->diff_mv = ch->mock_diff_mv;
	}

	/* 3. Convert differential mV to High-Voltage mV via divider ratio */
	ch->hv_mv = amc3330_diff_mv_to_hv_mv(ch->diff_mv);
	return 0;
}

/* ==========================================================================
 * Public API Implementation
 * ========================================================================== */

int bms_hv_sense_init(struct bms_hv_sense *hv)
{
	if (hv == NULL) {
		return -EINVAL;
	}

	int ret = init_single_channel(&hv->accu, "ACCU (U4)");
	if (ret < 0) {
		return ret;
	}

	ret = init_single_channel(&hv->dclink, "DC-LINK (U3)");
	if (ret < 0) {
		return ret;
	}

	return 0;
}

int bms_hv_sense_sample(struct bms_hv_sense *hv)
{
	if (hv == NULL) {
		return -EINVAL;
	}

	int ret_accu   = sample_single_channel(&hv->accu);
	int ret_dclink = sample_single_channel(&hv->dclink);

	if (ret_accu < 0) {
		return ret_accu;
	}
	return ret_dclink;
}
```

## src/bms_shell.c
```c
/**
 * @file bms_shell.c
 * @brief "bms" shell commands, served over the USB CDC-ACM virtual COM port.
 *
 *   bms status        Print state, faults, measurements and outputs.
 *   bms clear_faults  Manually clear latched faults (PC application command).
 */

#include <errno.h>
#include <stdlib.h>

#include <zephyr/kernel.h>
#include <zephyr/shell/shell.h>
#include <zephyr/sys/util.h>

#include "bms.h"

static const struct {
	uint32_t bit;
	const char *name;
} fault_names[] = {
	{ BMS_FAULT_CELL_OV,            "CELL_OV" },
	{ BMS_FAULT_CELL_UV,            "CELL_UV" },
	{ BMS_FAULT_OVER_TEMP,          "OVER_TEMP" },
	{ BMS_FAULT_UNDER_TEMP,         "UNDER_TEMP" },
	{ BMS_FAULT_OVER_CURRENT,       "OVER_CURRENT" },
	{ BMS_FAULT_AFE_COMM,           "AFE_COMM" },
	{ BMS_FAULT_OPEN_WIRE,          "OPEN_WIRE" },
	{ BMS_FAULT_PRECHARGE_TIMEOUT,  "PRECHARGE_TIMEOUT" },
	{ BMS_FAULT_IMPLAUSIBILITY,     "IMPLAUSIBILITY" },
	{ BMS_FAULT_CONTACTOR_DRV,      "CONTACTOR_DRV" },
	{ BMS_FAULT_REGEN_OVER_CURRENT, "REGEN_OVER_CURRENT" },
	{ BMS_FAULT_CHARGE_UNDER_TEMP,  "CHARGE_UNDER_TEMP" },
	{ BMS_FAULT_CURRENT_SENSOR,     "CURRENT_SENSOR" },
};

static void print_faults(const struct shell *sh, const char *label, uint32_t mask)
{
	shell_fprintf(sh, SHELL_NORMAL, "%-14s 0x%08X", label, mask);

	if (mask == BMS_FAULT_NONE) {
		shell_fprintf(sh, SHELL_NORMAL, " (none)");
	}

	ARRAY_FOR_EACH(fault_names, i) {
		if (mask & fault_names[i].bit) {
			shell_fprintf(sh, SHELL_NORMAL, " %s", fault_names[i].name);
		}
	}

	shell_fprintf(sh, SHELL_NORMAL, "\n");
}

static void print_ivt(const struct shell *sh, const struct ivt_s_data *ivt, int64_t now_ms)
{
	static const struct {
		enum ivt_s_channel ch;
		const char *name;
		const char *unit;
	} rows[] = {
		{ IVT_S_CH_I,  "I",  "mA" },
		{ IVT_S_CH_U1, "U1", "mV" },
		{ IVT_S_CH_U2, "U2", "mV" },
		{ IVT_S_CH_U3, "U3", "mV" },
	};

	ARRAY_FOR_EACH(rows, i) {
		const struct ivt_s_reading *r = &ivt->ch[rows[i].ch];

		if (!r->seen) {
			shell_print(sh, "%-14s %-2s no frames received", "IVT-S:", rows[i].name);
			continue;
		}

		shell_print(sh, "%-14s %-2s %d %s, %lld ms ago, state 0x%X%s%s%s%s", "IVT-S:",
			    rows[i].name, r->value, rows[i].unit, now_ms - r->rx_ms, r->state,
			    (r->state & IVT_S_STATE_OCS) ? " OCS" : "",
			    (r->state & IVT_S_STATE_RESULT_ERROR) ? " RESULT_ERROR" : "",
			    (r->state & IVT_S_STATE_ANY_MEAS_ERROR) ? " ANY_MEAS_ERROR" : "",
			    (r->state & IVT_S_STATE_SYSTEM_ERROR) ? " SYSTEM_ERROR" : "");
	}
}

static int cmd_bms_status(const struct shell *sh, size_t argc, char **argv)
{
	ARG_UNUSED(argc);
	ARG_UNUSED(argv);

	/* Copy under the lock so the printout is one consistent tick */
	struct bms_ctx c;

	bms_ctx_lock();
	c = *bms_ctx_get();
	bms_ctx_unlock();

	int64_t now_ms = k_uptime_get();

	shell_print(sh, "%-14s %s", "State:", bms_state_to_str(c.state));
	print_faults(sh, "Live faults:", c.live_faults);
	print_faults(sh, "Latched:", c.latched_faults);

	shell_print(sh, "%-14s min %u mV, max %u mV, sum %u mV", "Cells:",
		    c.min_cell_mv, c.max_cell_mv, c.sum_cells_mv);
	shell_print(sh, "%-14s min %d.%d C, max %d.%d C", "Temperature:",
		    c.min_temp_deci_c / 10, abs(c.min_temp_deci_c % 10),
		    c.max_temp_deci_c / 10, abs(c.max_temp_deci_c % 10));
	shell_print(sh, "%-14s pack %u mV, TS %u mV (sense %s)", "HV:",
		    c.pack_voltage_mv, c.ts_voltage_mv,
		    c.hv_sense_valid ? "valid" : "INVALID");
	shell_print(sh, "%-14s %d mA (positive = discharge)", "Current:",
		    c.pack_current_ma);
	print_ivt(sh, &c.ivt, now_ms);
	shell_print(sh, "%-14s %u mA (%s)", "Regen limit:",
		    c.out.max_regen_current_ma,
		    c.out.regen_allowed ? "allowed" : "blocked");

	shell_print(sh, "%-14s PC=%d AIR-=%d AIR+=%d SDC_FAULT=%d BAL=%d", "Outputs:",
		    c.out.precharge_closed, c.out.air_neg_closed,
		    c.out.air_pos_closed, c.out.sdc_fault_pin_active,
		    c.out.balancing_enabled);
	shell_print(sh, "%-14s TS_READY=%d TS_ACTIVE=%d TS_REQUEST=%d SDC_POWERED=%d",
		    "Handshake:", c.out.ts_ready, c.out.ts_active,
		    c.req.ts_request, c.sdc_airs_powered);

	return 0;
}

static int cmd_bms_clear_faults(const struct shell *sh, size_t argc, char **argv)
{
	ARG_UNUSED(argc);
	ARG_UNUSED(argv);

	struct bms_ctx *ctx = bms_ctx_get();
	bool in_fault_state;
	bool cleared = false;
	uint32_t live;
	bool ts_request;

	bms_ctx_lock();
	in_fault_state = (ctx->state == BMS_STATE_FAULT);
	if (in_fault_state) {
		cleared = bms_sm_clear_faults_from_pc(ctx);
	}
	live       = ctx->live_faults;
	ts_request = ctx->req.ts_request;
	bms_ctx_unlock();

	if (!in_fault_state) {
		shell_print(sh, "Nothing to clear: BMS is not in the FAULT state");
		return 0;
	}

	if (!cleared) {
		shell_error(sh, "Rejected: %s",
			    (live != BMS_FAULT_NONE) ? "a fault condition is still present"
						     : "TS request is still asserted");
		print_faults(sh, "Live faults:", live);
		shell_print(sh, "%-14s %d", "TS_REQUEST:", ts_request);
		return -EBUSY;
	}

	shell_print(sh, "Latched faults cleared");
	return 0;
}

SHELL_STATIC_SUBCMD_SET_CREATE(bms_cmds,
	SHELL_CMD(status, NULL, "Print BMS state, faults, measurements and outputs",
		  cmd_bms_status),
	SHELL_CMD(clear_faults, NULL, "Clear latched faults (only when no fault is present)",
		  cmd_bms_clear_faults),
	SHELL_SUBCMD_SET_END
);

SHELL_CMD_REGISTER(bms, &bms_cmds, "SUFST BMS commands", NULL);
```

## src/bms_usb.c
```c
/**
 * @file bms_usb.c
 * @brief USB clock recovery setup for the CDC-ACM shell port.
 *
 * The USB peripheral is clocked from the internal HSI48 oscillator, which is
 * not accurate enough for full-speed USB on its own. The Clock Recovery
 * System (CRS) trims HSI48 against the host's 1 kHz Start-Of-Frame packets.
 * Zephyr's STM32G4 clock driver does not configure the CRS, so it is done
 * here before the USB device stack starts.
 */

#include <zephyr/init.h>
#include <zephyr/kernel.h>

#include <stm32g4xx_ll_bus.h>
#include <stm32g4xx_ll_crs.h>

static int bms_usb_crs_init(void)
{
	LL_APB1_GRP1_EnableClock(LL_APB1_GRP1_PERIPH_CRS);

	/* Reset-default reload / error limit already match 48 MHz vs 1 kHz SOF */
	LL_CRS_SetSyncSignalSource(LL_CRS_SYNC_SOURCE_USB);
	LL_CRS_EnableAutoTrimming();
	LL_CRS_EnableFreqErrorCounter();

	return 0;
}

SYS_INIT(bms_usb_crs_init, PRE_KERNEL_1, CONFIG_KERNEL_INIT_PRIORITY_DEFAULT);
```
